# MM32F103xx register map
File version: 1.3
Registers are 32-bit, read-write, reset 0x0 unless marked. A register's access mark holds for its fields unless they carry their own. Offsets are from the block's base; [hi:lo] are bit positions; {n}, {i} and the like mark numbered series.

## ADC1 — Analog to digital converter
Base 0x40012400
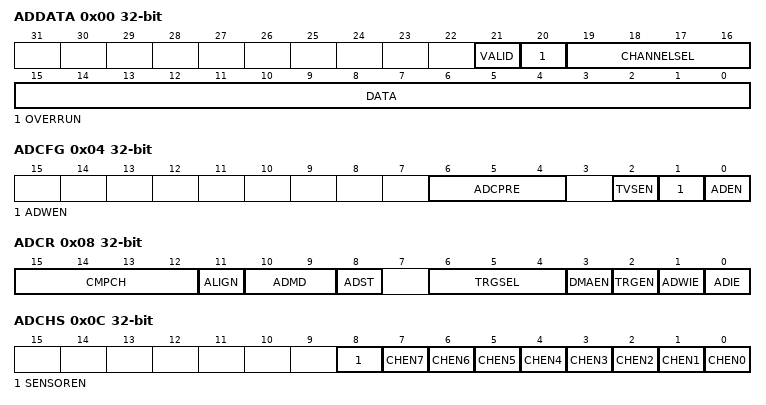
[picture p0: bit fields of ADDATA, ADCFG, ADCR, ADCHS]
0x00 ADDATA ro
  [21] VALID — Valid flag
  [20] OVERRUN — Overrun flag
  [19:16] CHANNELSEL — Channel selection
  [15:0] DATA — Transfer data
0x04 ADCFG
  [6:4] ADCPRE — ADC prescaler
  [2] TVSEN — Temperature sensor enable
  [1] ADWEN — ADC window comparison enable
  [0] ADEN — ADC enable
0x08 ADCR
  [15:12] CMPCH — Window comparison channel selection
  [11] ALIGN — Data alignment
  [10:9] ADMD — ADC mode
  [8] ADST — ADC start
  [6:4] TRGSEL — External trigger selection
  [3] DMAEN — Direct memory access enable
  [2] TRGEN — External trigger enable
  [1] ADWIE — ADC window comparator interrupt enable
  [0] ADIE — ADC interrupt enable
0x0C ADCHS
  [8] SENSOREN — Temperature sensor enable
  [n] CHEN{n} (n=0..7) — Analog input channel {n} enable
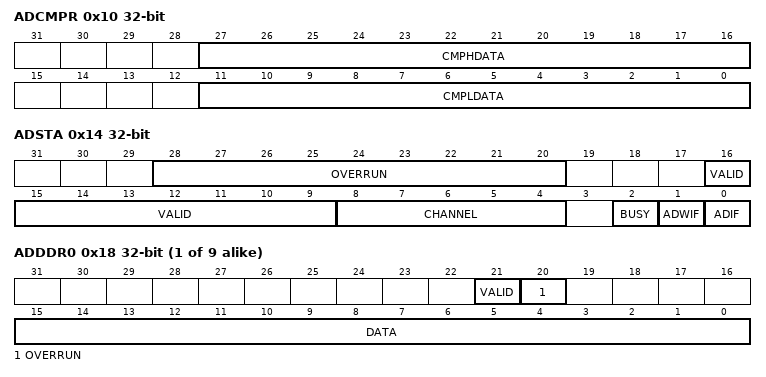
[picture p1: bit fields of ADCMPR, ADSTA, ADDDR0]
0x10 ADCMPR
  [27:16] CMPHDATA — Compare data high limit
  [11:0] CMPLDATA — Compare data low limit
0x14 ADSTA ro
  [28:20] OVERRUN — Overrun flag
  [16:9] VALID — Valid flag
  [8:4] CHANNEL — Current conversion channel
  [2] BUSY
  [1] ADWIF — ADC window comparator interrupt flag
  [0] ADIF — ADC interrupt flag
{0x18+4i} ADDDR{i} ro (i=0..8)
  [21] VALID — Valid flag
  [20] OVERRUN — Overrun flag
  [15:0] DATA — Transfer data

## ADC2 — Analog to digital converter
Base 0x40012800
Registers as ADC1, without ADDATA; these are added or differ:
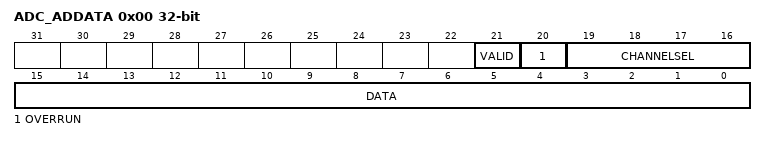
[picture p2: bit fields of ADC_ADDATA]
0x00 ADC_ADDATA ro
  [21] VALID — Valid flag
  [20] OVERRUN — Overrun flag
  [19:16] CHANNELSEL — Channel selection
  [15:0] DATA — Transfer data

## DAC — Digital to analog converter
Base 0x40007400
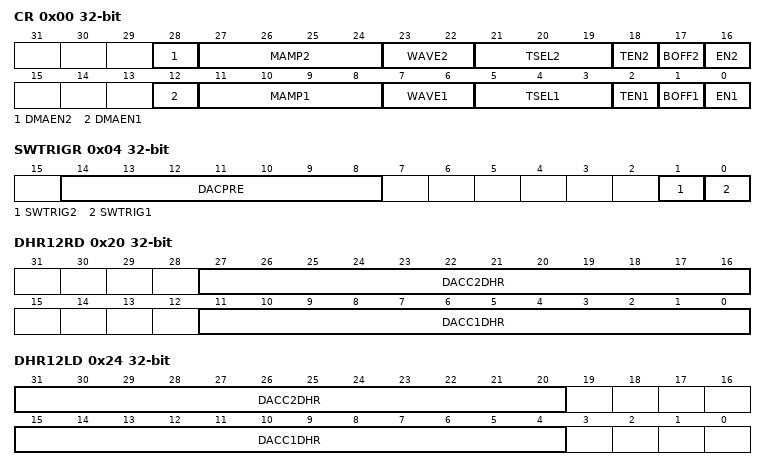
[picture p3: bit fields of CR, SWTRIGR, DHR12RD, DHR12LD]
0x00 CR
  [28] DMAEN2 — DAC channel2 DMA enable
  [27:24] MAMP2 — DAC channel2 mask/amplitude selector
  [23:22] WAVE2 — DAC channel2 noise/triangle wave generation enable
  [21:19] TSEL2 — DAC channel2 trigger selection
  [18] TEN2 — DAC channel2 trigger enable
  [17] BOFF2 — DAC channel2 output buffer disable
  [16] EN2 — DAC channel2 enable
  [12] DMAEN1 — DAC channel1 DMA enable
  [11:8] MAMP1 — DAC channel1 mask/amplitude selector
  [7:6] WAVE1 — DAC channel1 noise/triangle wave generation enable
  [5:3] TSEL1 — DAC channel1 trigger selection
  [2] TEN1 — DAC channel1 trigger enable
  [1] BOFF1 — DAC channel1 output buffer disable
  [0] EN1 — DAC channel1 enable
0x04 SWTRIGR wo
  [14:8] DACPRE — DAC prescale
  [1] SWTRIG2 — DAC channel2 software trigger
  [0] SWTRIG1 — DAC channel1 software trigger
0x08 DHR12R1
  [11:0] DACC1DHR — DAC channel1 12-bit right-aligned data
0x0C DHR12L1
  [15:4] DACC1DHR — DAC channel1 12-bit left-aligned data
0x10 DHR8R1
  [7:0] DACC1DHR — DAC channel1 8-bit right-aligned data
0x14 DHR12R2
  [11:0] DACC2DHR — DAC channel2 12-bit right-aligned data
0x18 DHR12L2
  [15:4] DAC2DHR — DAC channel2 12-bit left-aligned data
0x1C DHR8R2
  [7:0] DACC2DHR — DAC channel2 8-bit right-aligned data
0x20 DHR12RD
  [27:16] DACC2DHR — DAC channel2 12-bit right-aligned data
  [11:0] DACC1DHR — DAC channel1 12-bit right-aligned data
0x24 DHR12LD
  [31:20] DACC2DHR — DAC channel2 12-bit left-aligned data
  [15:4] DACC1DHR — DAC channel1 12-bit left-aligned data
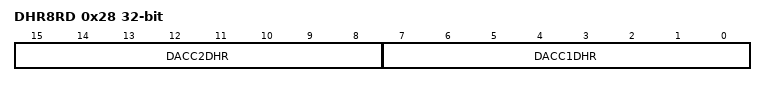
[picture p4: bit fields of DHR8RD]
0x28 DHR8RD
  [15:8] DACC2DHR — DAC channel2 8-bit right-aligned data
  [7:0] DACC1DHR — DAC channel1 8-bit right-aligned data
0x2C DOR1
  [11:0] DACC1DOR — DAC channel1 data output
0x30 DOR2
  [11:0] DACC2DOR — DAC channel2 data output

## DBG — Debug support
Base 0xE0042000
0x00 IDCODE ro
  [31:0] DEV_ID — Device identifier
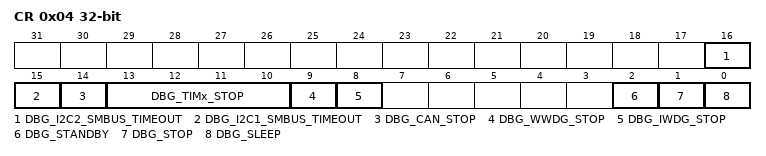
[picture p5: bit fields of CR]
0x04 CR wo
  [16] DBG_I2C2_SMBUS_TIMEOUT — SMBUS timeout mode stopped when Core is halted
  [15] DBG_I2C1_SMBUS_TIMEOUT — SMBUS timeout mode stopped when Core is halted
  [14] DBG_CAN_STOP — Debug CAN stopped when core is halted
  [13:10] DBG_TIMx_STOP — TIMx counter stopped when core is halted
  [9] DBG_WWDG_STOP — Debug window watchdog when core is halted
  [8] DBG_IWDG_STOP — Debug independent watchdog stopped when core is stopped
  [2] DBG_STANDBY — Debug Standby mode
  [1] DBG_STOP — Debug Stop mode
  [0] DBG_SLEEP — Debug Sleep mode

## CRC — CRC calculation unit
Base 0x40023000
0x00 DR
  [31:0] DR — Data register bits
0x04 IDR
  [7:0] IDR — General-purpose 8-bit data register bits
0x08 CTRL wo
  [0] RESET — CRC reset

## USB — Universal serial bus full-speed device interface
Base 0x40005C00
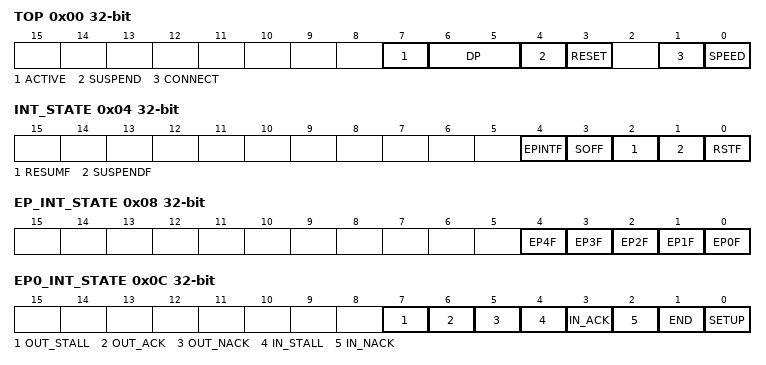
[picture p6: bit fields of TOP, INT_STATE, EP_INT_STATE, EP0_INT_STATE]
0x00 TOP
  [7] ACTIVE — USB bus is active
  [6:5] DP — Current USB DP/DM line state
  [4] SUSPEND — USB suspend state
  [3] RESET — Reset EP and FIFO in USB controller
  [1] CONNECT — USB connection
  [0] SPEED
0x04 INT_STATE ro
  [4] EPINTF — EP interrupt received
  [3] SOFF — BUS received
  [2] RESUMF — BUS resume received
  [1] SUSPENDF — BUS suspend received
  [0] RSTF — BUS reset received
0x08 EP_INT_STATE ro
  [n] EP{n}F (n=0..4) — EP{n} interrupt received
0x0C EP0_INT_STATE ro
  [7] OUT_STALL — OUT-STALL received
  [6] OUT_ACK — OUT-ACK received
  [5] OUT_NACK — OUT-NACK received
  [4] IN_STALL — IN-STALL received
  [3] IN_ACK — IN-ACK received
  [2] IN_NACK — IN-NACK received
  [1] END — Status stage finished
  [0] SETUP — SETUP packet received
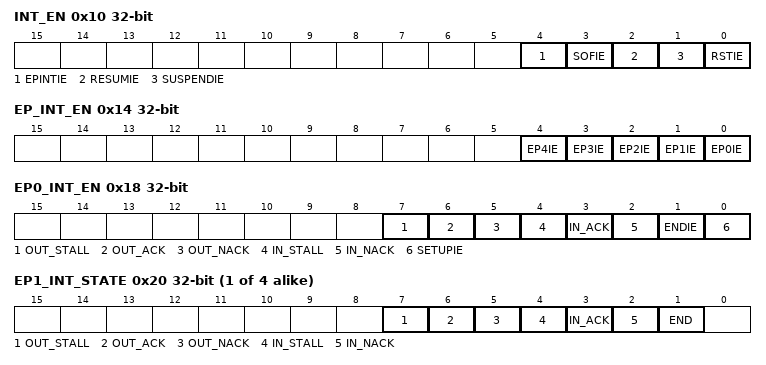
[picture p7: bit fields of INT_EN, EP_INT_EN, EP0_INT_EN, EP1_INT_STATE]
0x10 INT_EN
  [4] EPINTIE — EP interrupt enable
  [3] SOFIE — SOF interrupt enable
  [2] RESUMIE — BUS resume interrupt enable
  [1] SUSPENDIE — BUS suspend interrupt enable
  [0] RSTIE — BUS reset interrupt enable
0x14 EP_INT_EN
  [n] EP{n}IE (n=0..4) — EP{n} interrupt enable
0x18 EP0_INT_EN
  [7] OUT_STALL — OUT-STALL interrupt enable
  [6] OUT_ACK — OUT-ACK interrupt enable
  [5] OUT_NACK — OUT-NACK interrupt enable
  [4] IN_STALL — IN-STALL interrupt enable
  [3] IN_ACK — IN-ACK interrupt enable
  [2] IN_NACK — IN-NACK interrupt enable
  [1] ENDIE — Status stage finished interrupt enable
  [0] SETUPIE — SETUP packet interrupt enable
{0x1C+4i} EP{i}_INT_STATE (i=1..4)
  [7] OUT_STALL — OUT-STALL received
  [6] OUT_ACK — OUT-ACK received
  [5] OUT_NACK — OUT-NACK received
  [4] IN_STALL — IN-STALL received
  [3] IN_ACK — IN-ACK received
  [2] IN_NACK — IN-NACK received
  [1] END — Transfer finished
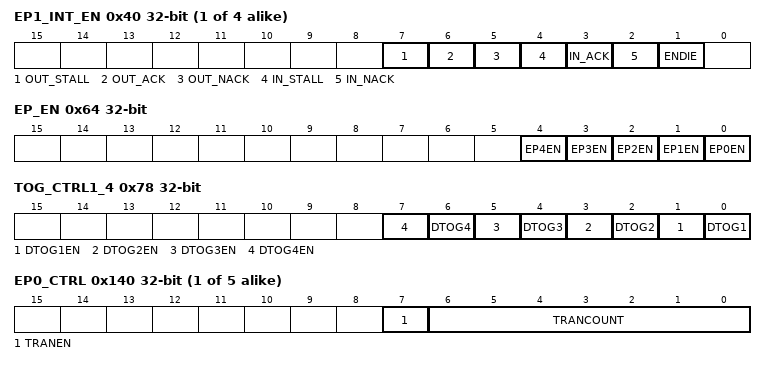
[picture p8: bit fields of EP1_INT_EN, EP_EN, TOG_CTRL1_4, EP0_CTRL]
{0x3C+4i} EP{i}_INT_EN (i=1..4)
  [7] OUT_STALL — OUT-STALL interrupt enable
  [6] OUT_ACK — OUT-ACK interrupt enable
  [5] OUT_NACK — OUT-NACK interrupt enable
  [4] IN_STALL — IN-STALL interrupt enable
  [3] IN_ACK — IN-ACK interrupt enable
  [2] IN_NACK — IN-NACK interrupt enable
  [1] ENDIE — Finished interrupt enable
0x60 ADDR
  [6:0] ADDR — USB address
0x64 EP_EN
  [n] EP{n}EN (n=0..4) — Enable End Point {n}
0x78 TOG_CTRL1_4
  [2n-1] DTOG{n}EN (n=1..4) — Set End Point {n} enable
  [2n-2] DTOG{n} (n=1..4) — Set End Point {n} Toggle
{0x80+4i} SETUP{i} ro (i=0..7)
  [7:0] SETUPD{i} — Setup Data {i}
0xA0 PACKET_SIZE reset 0x40
  [7:0] SIZE0 — USB DMA Max Packet Size
{0x100+4i} EP{i}_AVAIL ro (i=0..4)
  [7:0] EP{i}AVIL — EP{i} FIFO available data number
{0x140+4i} EP{i}_CTRL (i=0..4)
  [7] TRANEN — EP{i} transfer enable
  [6:0] TRANCOUNT — EP{i} transfer counter
{0x160+4i} EP{i}_FIFO (i=0..4)
  [7:0] EP{i}_FIFO — EP{i} FIFO port
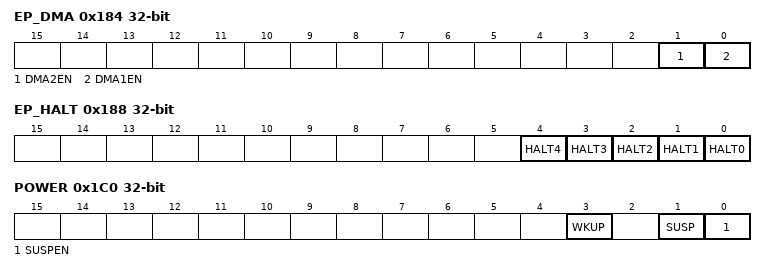
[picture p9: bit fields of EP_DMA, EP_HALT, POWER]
0x184 EP_DMA
  [1] DMA2EN — EP2 DMA enable
  [0] DMA1EN — EP1 DMA enable
0x188 EP_HALT
  [n] HALT{n} (n=0..4) — EP{n} halt
0x1C0 POWER
  [3] WKUP — Enable controller wake up from suspend state
  [1] SUSP — suspend
  [0] SUSPEN — BUS suspend enable bit
